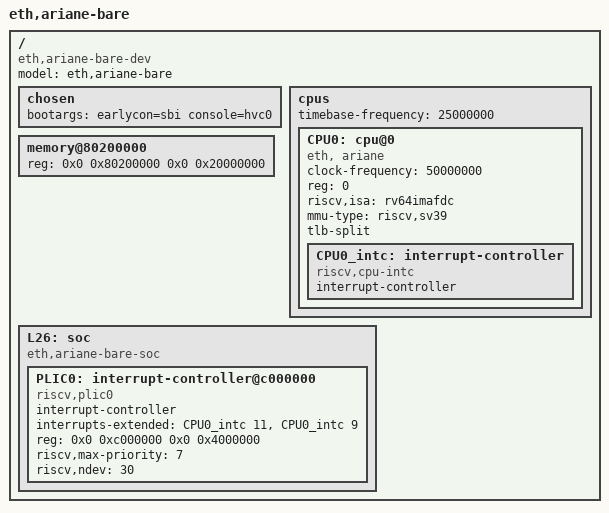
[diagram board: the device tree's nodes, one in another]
/dts-v1/;

/ {
  #address-cells = <2>;
  #size-cells = <2>;
  compatible = "eth,ariane-bare-dev";
  model = "eth,ariane-bare";
  chosen {
    bootargs = "earlycon=sbi console=hvc0";
  };
  cpus {
    #address-cells = <1>;
    #size-cells = <0>;
    timebase-frequency = <25000000>; // 25 MHz
    CPU0: cpu@0 {
      clock-frequency = <50000000>; // 50 MHz
      device_type = "cpu";
      reg = <0>;
      status = "okay";
      compatible = "eth, ariane", "riscv";
      riscv,isa = "rv64imafdc";
      mmu-type = "riscv,sv39";
      tlb-split;
      // HLIC - hart local interrupt controller
      CPU0_intc: interrupt-controller {
        #interrupt-cells = <1>;
        interrupt-controller;
        compatible = "riscv,cpu-intc";
      };
    };
  };
  memory@80200000 {
    device_type = "memory";
    reg = <0x0 0x80200000 0x0 0x20000000>;
  };
  L26: soc {
    #address-cells = <2>;
    #size-cells = <2>;
    compatible = "eth,ariane-bare-soc", "simple-bus";
    ranges;

    PLIC0: interrupt-controller@c000000 {
      #address-cells = <0>;
      #interrupt-cells = <1>;
      compatible = "riscv,plic0";
      interrupt-controller;
      interrupts-extended = <&CPU0_intc 11 &CPU0_intc 9>;
      reg = <0x0 0xc000000 0x0 0x4000000>;
      riscv,max-priority = <7>;
      riscv,ndev = <30>;
    };
  };
};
